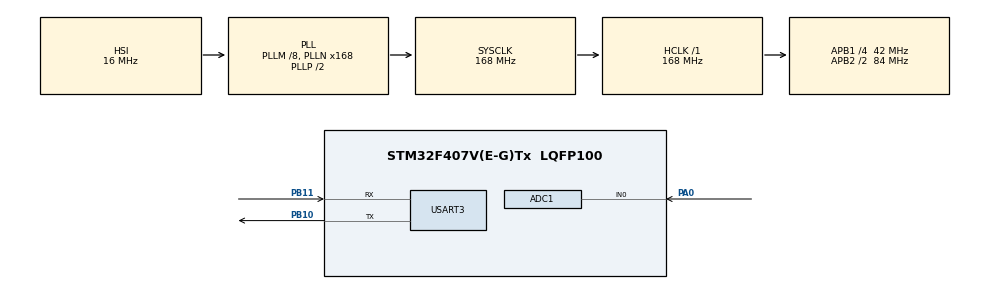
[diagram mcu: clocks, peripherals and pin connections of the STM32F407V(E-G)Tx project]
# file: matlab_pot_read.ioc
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ADC1.Channel-0\#ChannelRegularConversion=ADC_CHANNEL_0
ADC1.ContinuousConvMode=ENABLE
ADC1.NbrOfConversionFlag=1
ADC1.Rank-0\#ChannelRegularConversion=1
ADC1.SamplingTime-0\#ChannelRegularConversion=ADC_SAMPLETIME_3CYCLES
ADC1.ScanConvMode=ENABLE
ADC1.master=1
Mcu.Family=STM32F4
Mcu.Name=STM32F407V(E-G)Tx
Mcu.Package=LQFP100
NVIC.PriorityGroup=NVIC_PRIORITYGROUP_4
PA0-WKUP.Signal=ADCx_IN0
PA13.Mode=Serial_Wire
PA13.Signal=SYS_JTMS-SWDIO
PA14.Mode=Serial_Wire
PA14.Signal=SYS_JTCK-SWCLK
PB10.Mode=Asynchronous
PB10.Signal=USART3_TX
PB11.Mode=Asynchronous
PB11.Signal=USART3_RX
PH0-OSC_IN.Mode=HSE-External-Oscillator
PH0-OSC_IN.Signal=RCC_OSC_IN
PH1-OSC_OUT.Mode=HSE-External-Oscillator
PH1-OSC_OUT.Signal=RCC_OSC_OUT
ProjectManager.HeapSize=0x200
ProjectManager.StackSize=0x400
ProjectManager.TargetToolchain=MDK-ARM V5.27
RCC.48MHZClocksFreq_Value=84000000
RCC.AHBFreq_Value=168000000
RCC.APB1CLKDivider=RCC_HCLK_DIV4
RCC.APB1Freq_Value=42000000
RCC.APB1TimFreq_Value=84000000
RCC.APB2CLKDivider=RCC_HCLK_DIV2
RCC.APB2Freq_Value=84000000
RCC.APB2TimFreq_Value=168000000
RCC.CortexFreq_Value=168000000
RCC.HCLKFreq_Value=168000000
RCC.HSE_VALUE=25000000
RCC.HSI_VALUE=16000000
RCC.LSE_VALUE=32768
RCC.PLLM=8
RCC.PLLN=168
RCC.SYSCLKFreq_VALUE=168000000
RCC.SYSCLKSource=RCC_SYSCLKSOURCE_PLLCLK
RCC.VCOOutputFreq_Value=336000000
SH.ADCx_IN0.0=ADC1_IN0,IN0
USART3.VirtualMode=VM_ASYNC
board=custom

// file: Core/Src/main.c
/* USER CODE BEGIN Header */
/**
  ******************************************************************************
  * @file           : main.c
  * @brief          : Main program body
  ******************************************************************************
  * @attention
  *
  * <h2><center>&copy; Copyright (c) 2020 STMicroelectronics.
  * All rights reserved.</center></h2>
  *
  * This software component is licensed by ST under BSD 3-Clause license,
  * the "License"; You may not use this file except in compliance with the
  * License. You may obtain a copy of the License at:
  *                        opensource.org/licenses/BSD-3-Clause
  *
  ******************************************************************************
  */
/* USER CODE END Header */
#include "main.h"

/* USER CODE BEGIN PM */
uint16_t value = 0;
int data = 0;

char pData[50];

/* USER CODE END PM */

ADC_HandleTypeDef hadc1;

UART_HandleTypeDef huart3;

void SystemClock_Config(void);
static void MX_GPIO_Init(void);
static void MX_ADC1_Init(void);
static void MX_USART3_UART_Init(void);

int main(void)
{

  /* MCU Configuration--------------------------------------------------------*/

  /* Reset of all peripherals, Initializes the Flash interface and the Systick. */
  HAL_Init();

  /* Configure the system clock */
  SystemClock_Config();

  /* Initialize all configured peripherals */
  MX_GPIO_Init();
  MX_ADC1_Init();
  MX_USART3_UART_Init();
  /* USER CODE BEGIN 2 */
	HAL_ADC_Start(&hadc1);

  /* USER CODE END 2 */

  /* Infinite loop */
  /* USER CODE BEGIN WHILE */
  while (1)
  {
  HAL_ADC_Start(&hadc1);
  HAL_ADC_PollForConversion(&hadc1, 100);
  value = HAL_ADC_GetValue(&hadc1);
  HAL_ADC_Stop (&hadc1);
	HAL_UART_Transmit(&huart3,(uint8_t*)pData,sprintf(pData,"%d\n",value),100);
	HAL_Delay(1000);
    /* USER CODE END WHILE */

  }
}

void SystemClock_Config(void)
{
  RCC_OscInitTypeDef RCC_OscInitStruct = {0};
  RCC_ClkInitTypeDef RCC_ClkInitStruct = {0};

  /** Configure the main internal regulator output voltage
  */
  __HAL_RCC_PWR_CLK_ENABLE();
  __HAL_PWR_VOLTAGESCALING_CONFIG(PWR_REGULATOR_VOLTAGE_SCALE1);
  /** Initializes the RCC Oscillators according to the specified parameters
  * in the RCC_OscInitTypeDef structure.
  */
  RCC_OscInitStruct.OscillatorType = RCC_OSCILLATORTYPE_HSI;
  RCC_OscInitStruct.HSIState = RCC_HSI_ON;
  RCC_OscInitStruct.HSICalibrationValue = RCC_HSICALIBRATION_DEFAULT;
  RCC_OscInitStruct.PLL.PLLState = RCC_PLL_ON;
  RCC_OscInitStruct.PLL.PLLSource = RCC_PLLSOURCE_HSI;
  RCC_OscInitStruct.PLL.PLLM = 8;
  RCC_OscInitStruct.PLL.PLLN = 168;
  RCC_OscInitStruct.PLL.PLLP = RCC_PLLP_DIV2;
  RCC_OscInitStruct.PLL.PLLQ = 4;
  if (HAL_RCC_OscConfig(&RCC_OscInitStruct) != HAL_OK)
  {
    Error_Handler();
  }
  /** Initializes the CPU, AHB and APB buses clocks
  */
  RCC_ClkInitStruct.ClockType = RCC_CLOCKTYPE_HCLK|RCC_CLOCKTYPE_SYSCLK
                              |RCC_CLOCKTYPE_PCLK1|RCC_CLOCKTYPE_PCLK2;
  RCC_ClkInitStruct.SYSCLKSource = RCC_SYSCLKSOURCE_PLLCLK;
  RCC_ClkInitStruct.AHBCLKDivider = RCC_SYSCLK_DIV1;
  RCC_ClkInitStruct.APB1CLKDivider = RCC_HCLK_DIV4;
  RCC_ClkInitStruct.APB2CLKDivider = RCC_HCLK_DIV2;

  if (HAL_RCC_ClockConfig(&RCC_ClkInitStruct, FLASH_LATENCY_5) != HAL_OK)
  {
    Error_Handler();
  }
}

static void MX_ADC1_Init(void)
{

  ADC_ChannelConfTypeDef sConfig = {0};

  /** Configure the global features of the ADC (Clock, Resolution, Data Alignment and number of conversion)
  */
  hadc1.Instance = ADC1;
  hadc1.Init.ClockPrescaler = ADC_CLOCK_SYNC_PCLK_DIV4;
  hadc1.Init.Resolution = ADC_RESOLUTION_12B;
  hadc1.Init.ScanConvMode = ENABLE;
  hadc1.Init.ContinuousConvMode = ENABLE;
  hadc1.Init.DiscontinuousConvMode = DISABLE;
  hadc1.Init.ExternalTrigConvEdge = ADC_EXTERNALTRIGCONVEDGE_NONE;
  hadc1.Init.ExternalTrigConv = ADC_SOFTWARE_START;
  hadc1.Init.DataAlign = ADC_DATAALIGN_RIGHT;
  hadc1.Init.NbrOfConversion = 1;
  hadc1.Init.DMAContinuousRequests = DISABLE;
  hadc1.Init.EOCSelection = ADC_EOC_SINGLE_CONV;
  if (HAL_ADC_Init(&hadc1) != HAL_OK)
  {
    Error_Handler();
  }
  /** Configure for the selected ADC regular channel its corresponding rank in the sequencer and its sample time.
  */
  sConfig.Channel = ADC_CHANNEL_0;
  sConfig.Rank = 1;
  sConfig.SamplingTime = ADC_SAMPLETIME_3CYCLES;
  if (HAL_ADC_ConfigChannel(&hadc1, &sConfig) != HAL_OK)
  {
    Error_Handler();
  }

}

static void MX_USART3_UART_Init(void)
{

  huart3.Instance = USART3;
  huart3.Init.BaudRate = 115200;
  huart3.Init.WordLength = UART_WORDLENGTH_8B;
  huart3.Init.StopBits = UART_STOPBITS_1;
  huart3.Init.Parity = UART_PARITY_NONE;
  huart3.Init.Mode = UART_MODE_TX_RX;
  huart3.Init.HwFlowCtl = UART_HWCONTROL_NONE;
  huart3.Init.OverSampling = UART_OVERSAMPLING_16;
  if (HAL_UART_Init(&huart3) != HAL_OK)
  {
    Error_Handler();
  }

}

static void MX_GPIO_Init(void)
{

  /* GPIO Ports Clock Enable */
  __HAL_RCC_GPIOH_CLK_ENABLE();
  __HAL_RCC_GPIOA_CLK_ENABLE();
  __HAL_RCC_GPIOB_CLK_ENABLE();

}

void Error_Handler(void)
{
}

/************************ (C) COPYRIGHT STMicroelectronics *****END OF FILE****/
